# GPIO_GPIO_00600000h register map
Vendor: Texas Instruments
Peripheral module from a debugger description file (folder AM275x).
Registers are 32-bit, access not given, reset 0x0 unless marked. A register's access mark holds for its fields unless they carry their own. Offsets are as the file gives them; lines under a group give offsets from that group; [hi:lo] are bit positions; {n}, {i} and the like mark numbered series; 'fields as' and 'values as' point back to an identical list; <NAME> marks a mode.

## gpio
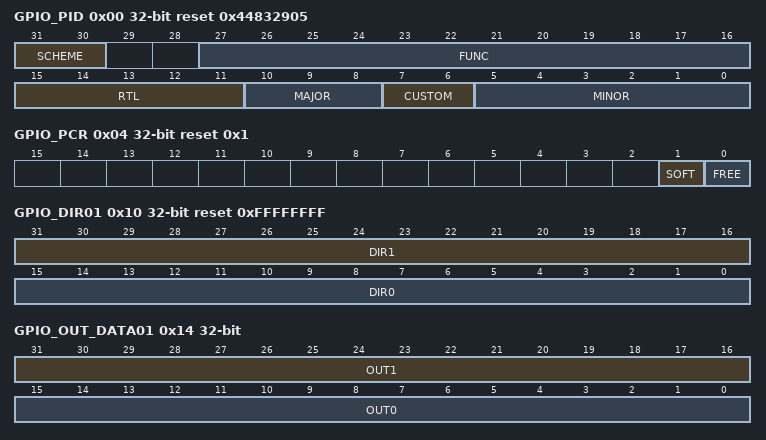
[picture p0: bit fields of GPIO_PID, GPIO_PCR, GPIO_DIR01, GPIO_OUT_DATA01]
0x00 GPIO_PID ro reset 0x44832905 — GPIO Periperal ID Register
  [31:30] SCHEME — Current scheme Reset Source: mod_g_srst_n
  [27:16] FUNC — Function code assigned to TCP3 Reset Source: mod_g_srst_n
  [15:11] RTL — RTL Version R code Reset Source: mod_g_srst_n
  [10:8] MAJOR — Major revision X code Reset Source: mod_g_srst_n
  [7:6] CUSTOM — Custom version code Reset Source: mod_g_srst_n
  [5:0] MINOR — Minor revision Y code Reset Source: mod_g_srst_n
0x04 GPIO_PCR ro reset 0x1 — Peripheral Control Register
  [1] SOFT — Used in conjunction with FREE bit to determine the emulation suspend mode. Reset Source: mod_g_srst_n
  [0] FREE — For GPIO, the FREE bit is fixed at 1, which means GPIO runs free in emulation suspend. Reset Source: mod_g_srst_n
0x08 GPIO_BINTEN rw — Bit Interrupt Enable Register
  [15:0] EN — Per bank interrupt enable. 0 = disable, 1 = enable. Reset Source: mod_g_srst_n
0x10 GPIO_DIR01 rw reset 0xFFFFFFFF — Direction Register
  [31:16] DIR1 — Direction of GPIO bank 1 bits, 0 = output, 1 = input. Reset Source: mod_g_srst_n
  [15:0] DIR0 — Direction of GPIO bank 0 bits, 0 = output, 1 = input. Reset Source: mod_g_srst_n
0x14 GPIO_OUT_DATA01 rw — Output Drive State Register
  [31:16] OUT1 — Output drive state of GPIO bank 1 bits, does not affect operation when it is configured as input. Reading it returns the output drive state. Reset Source: mod_g_srst_n
  [15:0] OUT0 — Output drive state of GPIO bank 0 bits, does not affect operation when it is configured as input. Reading it returns the output drive state. Reset Source: mod_g_srst_n
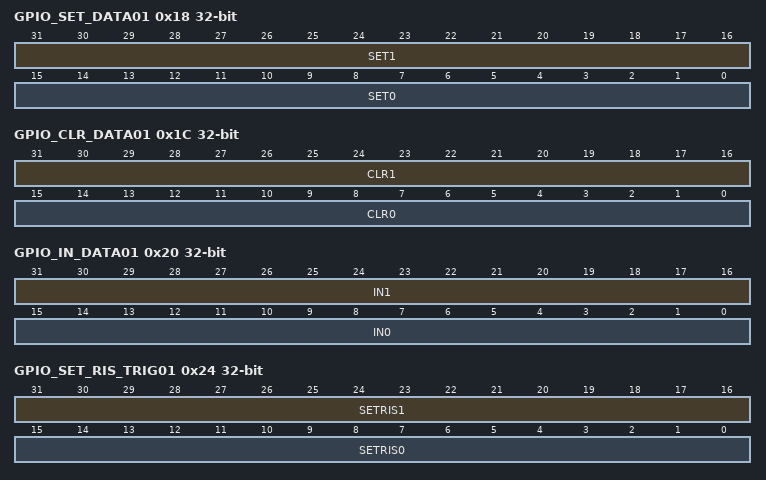
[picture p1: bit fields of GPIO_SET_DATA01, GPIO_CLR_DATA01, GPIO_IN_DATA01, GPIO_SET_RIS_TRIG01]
0x18 GPIO_SET_DATA01 — Set Output Drive State Register
  [31:16] SET1 — Writing 1 sets the output drive state of GPIO bank 1 bits. Reading it returns the output drive state. Reset Source: mod_g_srst_n (access R/W1TS)
  [15:0] SET0 — Writing 1 sets the output drive state of GPIO bank 0 bits. Reading it returns the output drive state. Reset Source: mod_g_srst_n (access R/W1TS)
0x1C GPIO_CLR_DATA01 — Clear Output Drive State Register
  [31:16] CLR1 — Writing 1 clears the output drive state of GPIO. Reading it returns the output drive state. Reset Source: mod_g_srst_n (access R/W1TC)
  [15:0] CLR0 — Writing 1 clears the output drive state of GPIO. Reading it returns the output drive state. Reset Source: mod_g_srst_n (access R/W1TC)
0x20 GPIO_IN_DATA01 ro — Bank Status Register
  [31:16] IN1 — Status of GPIO bank 1 bits. Reset Source: mod_g_srst_n
  [15:0] IN0 — Status of GPIO bank 0 bits. Reset Source: mod_g_srst_n
0x24 GPIO_SET_RIS_TRIG01 — Set Rising Edge Detection Register
  [31:16] SETRIS1 — Writing 1 enables rising edge detection for GPIO bank 1 bits. Reset Source: mod_g_srst_n (access R/W1TS)
  [15:0] SETRIS0 — Writing 1 enables rising edge detection for GPIO bank 0 bits. Reset Source: mod_g_srst_n (access R/W1TS)
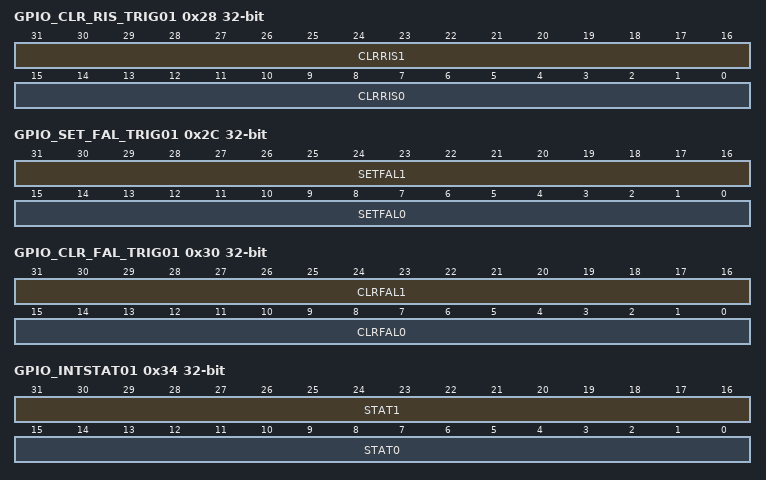
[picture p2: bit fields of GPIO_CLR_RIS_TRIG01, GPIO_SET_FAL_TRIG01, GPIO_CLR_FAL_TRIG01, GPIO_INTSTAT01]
0x28 GPIO_CLR_RIS_TRIG01 — Clear Rising Edge Detection Register
  [31:16] CLRRIS1 — Writing 1 clears rising edge detection for GPIO bank 1 bits. Reset Source: mod_g_srst_n (access R/W1TC)
  [15:0] CLRRIS0 — Writing 1 clears rising edge detection for GPIO bank 0 bits. Reset Source: mod_g_srst_n (access R/W1TC)
0x2C GPIO_SET_FAL_TRIG01 — Set Falling Edge Detection Register
  [31:16] SETFAL1 — Writing 1 enables falling edge detection for for GPIO bank 1 bits. Reset Source: mod_g_srst_n (access R/W1TS)
  [15:0] SETFAL0 — Writing 1 enables falling edge detection for for GPIO bank 0 bits. Reset Source: mod_g_srst_n (access R/W1TS)
0x30 GPIO_CLR_FAL_TRIG01 — Clear Falling Edge Detection Register
  [31:16] CLRFAL1 — Writing 1 clears falling edge detection for for GPIO bank 1 bits. Reset Source: mod_g_srst_n (access R/W1TC)
  [15:0] CLRFAL0 — Writing 1 clears falling edge detection for for GPIO bank 0 bits. Reset Source: mod_g_srst_n (access R/W1TC)
0x34 GPIO_INTSTAT01 — Bank Interrupt Status Register
  [31:16] STAT1 — Status of GPIO bank 0 bits interrupt. Reading back 1 = interrupt occurred. 0 = interrupt hasnt occurred since last cleared. Writing 1 clears the corresponding interrupt status. Reset Source: mod_g_srst_n (access R/W1TC)
  [15:0] STAT0 — Status of GPIO bank 0 bits interrupt. Reading back 1 = interrupt occurred. 0 = interrupt hasnt occurred since last cleared. Writing 1 clears the corresponding interrupt status. Reset Source: mod_g_srst_n (access R/W1TC)
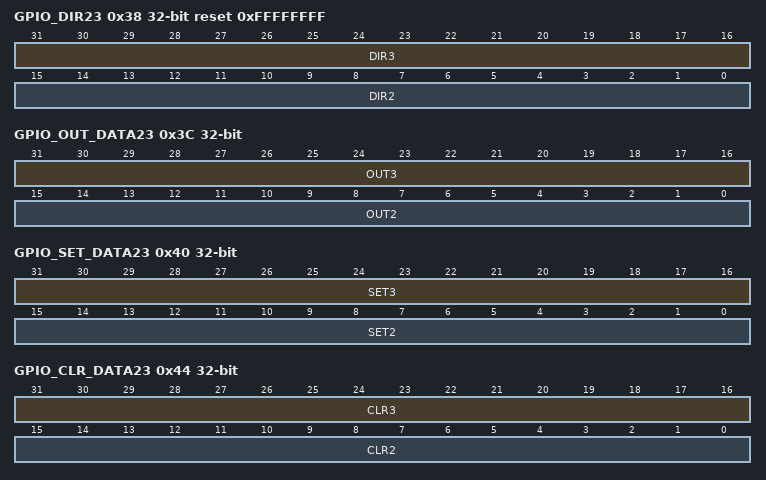
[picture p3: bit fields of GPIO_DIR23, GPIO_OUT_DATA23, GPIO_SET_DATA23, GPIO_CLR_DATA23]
0x38 GPIO_DIR23 rw reset 0xFFFFFFFF — Direction Register
  [31:16] DIR3 — Direction of GPIO bank 3 bits, 0 = output, 1 = input. Reset Source: mod_g_srst_n
  [15:0] DIR2 — Direction of GPIO bank 2 bits, 0 = output, 1 = input. Reset Source: mod_g_srst_n
0x3C GPIO_OUT_DATA23 rw — Output Drive State Register
  [31:16] OUT3 — Output drive state of GPIO bank 3 bits, does not affect operation when it is configured as input. Reading it returns the output drive state. Reset Source: mod_g_srst_n
  [15:0] OUT2 — Output drive state of GPIO bank 2 bits, does not affect operation when it is configured as input. Reading it returns the output drive state. Reset Source: mod_g_srst_n
0x40 GPIO_SET_DATA23 — Set Output Drive State Register
  [31:16] SET3 — Writing 1 sets the output drive state of GPIO bank 3 bits. Reading it returns the output drive state. Reset Source: mod_g_srst_n (access R/W1TS)
  [15:0] SET2 — Writing 1 sets the output drive state of GPIO bank 2 bits. Reading it returns the output drive state. Reset Source: mod_g_srst_n (access R/W1TS)
0x44 GPIO_CLR_DATA23 — Clear Output Drive State Register
  [31:16] CLR3 — Writing 1 clears the output drive state of GPIO. Reading it returns the output drive state. Reset Source: mod_g_srst_n (access R/W1TC)
  [15:0] CLR2 — Writing 1 clears the output drive state of GPIO. Reading it returns the output drive state. Reset Source: mod_g_srst_n (access R/W1TC)
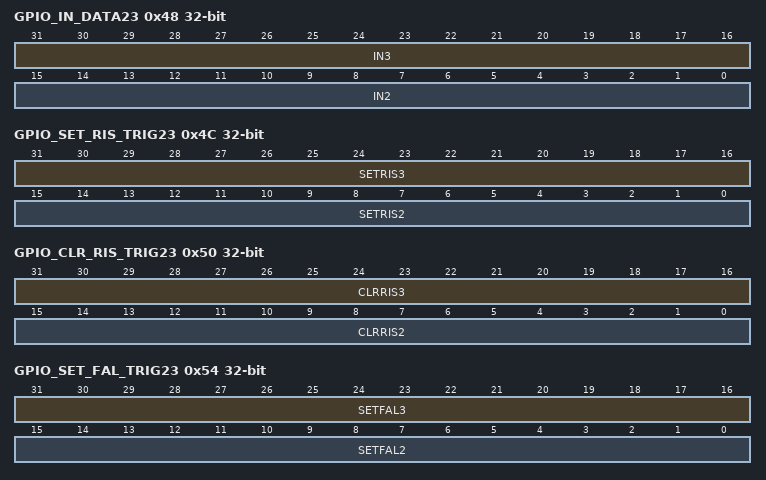
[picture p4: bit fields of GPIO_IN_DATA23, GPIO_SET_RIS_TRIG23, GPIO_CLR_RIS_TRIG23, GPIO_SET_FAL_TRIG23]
0x48 GPIO_IN_DATA23 ro — Bank Status Register
  [31:16] IN3 — Status of GPIO bank 3 bits. Reset Source: mod_g_srst_n
  [15:0] IN2 — Status of GPIO bank 2 bits. Reset Source: mod_g_srst_n
0x4C GPIO_SET_RIS_TRIG23 — Set Rising Edge Detection Register
  [31:16] SETRIS3 — Writing 1 enables rising edge detection for GPIO bank 3 bits. Reset Source: mod_g_srst_n (access R/W1TS)
  [15:0] SETRIS2 — Writing 1 enables rising edge detection for GPIO bank 2 bits. Reset Source: mod_g_srst_n (access R/W1TS)
0x50 GPIO_CLR_RIS_TRIG23 — Clear Rising Edge Detection Register
  [31:16] CLRRIS3 — Writing 1 clears rising edge detection for GPIO bank 3 bits. Reset Source: mod_g_srst_n (access R/W1TC)
  [15:0] CLRRIS2 — Writing 1 clears rising edge detection for GPIO bank 2 bits. Reset Source: mod_g_srst_n (access R/W1TC)
0x54 GPIO_SET_FAL_TRIG23 — Set Falling Edge Detection Register
  [31:16] SETFAL3 — Writing 1 enables falling edge detection for for GPIO bank 3 bits. Reset Source: mod_g_srst_n (access R/W1TS)
  [15:0] SETFAL2 — Writing 1 enables falling edge detection for for GPIO bank 2 bits. Reset Source: mod_g_srst_n (access R/W1TS)
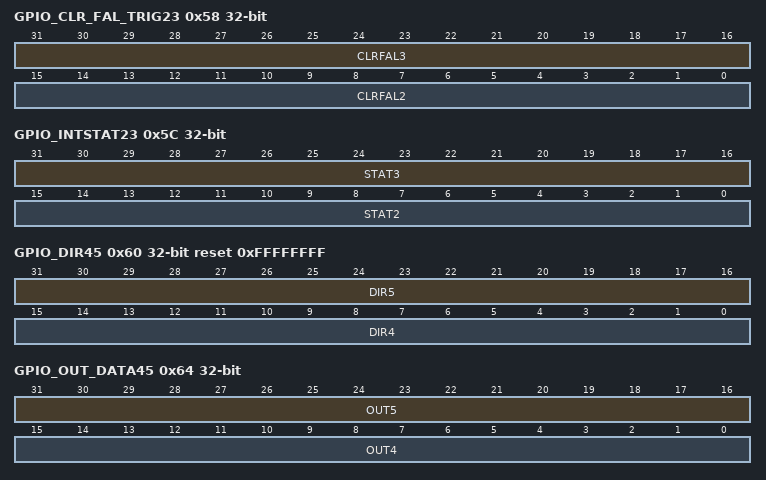
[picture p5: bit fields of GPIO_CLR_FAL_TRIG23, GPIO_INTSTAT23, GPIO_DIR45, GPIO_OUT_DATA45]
0x58 GPIO_CLR_FAL_TRIG23 — Clear Falling Edge Detection Register
  [31:16] CLRFAL3 — Writing 1 clears falling edge detection for for GPIO bank 3 bits. Reset Source: mod_g_srst_n (access R/W1TC)
  [15:0] CLRFAL2 — Writing 1 clears falling edge detection for for GPIO bank 2 bits. Reset Source: mod_g_srst_n (access R/W1TC)
0x5C GPIO_INTSTAT23 — Bank Interrupt Status Register
  [31:16] STAT3 — Status of GPIO bank 2 bits interrupt. Reading back 1 = interrupt occurred. 0 = interrupt hasnt occurred since last cleared. Writing 1 clears the corresponding interrupt status. Reset Source: mod_g_srst_n (access R/W1TC)
  [15:0] STAT2 — Status of GPIO bank 2 bits interrupt. Reading back 1 = interrupt occurred. 0 = interrupt hasnt occurred since last cleared. Writing 1 clears the corresponding interrupt status. Reset Source: mod_g_srst_n (access R/W1TC)
0x60 GPIO_DIR45 rw reset 0xFFFFFFFF — Direction Register
  [31:16] DIR5 — Direction of GPIO bank 5 bits, 0 = output, 1 = input. Reset Source: mod_g_srst_n
  [15:0] DIR4 — Direction of GPIO bank 4 bits, 0 = output, 1 = input. Reset Source: mod_g_srst_n
0x64 GPIO_OUT_DATA45 rw — Output Drive State Register
  [31:16] OUT5 — Output drive state of GPIO bank 5 bits, does not affect operation when it is configured as input. Reading it returns the output drive state. Reset Source: mod_g_srst_n
  [15:0] OUT4 — Output drive state of GPIO bank 4 bits, does not affect operation when it is configured as input. Reading it returns the output drive state. Reset Source: mod_g_srst_n
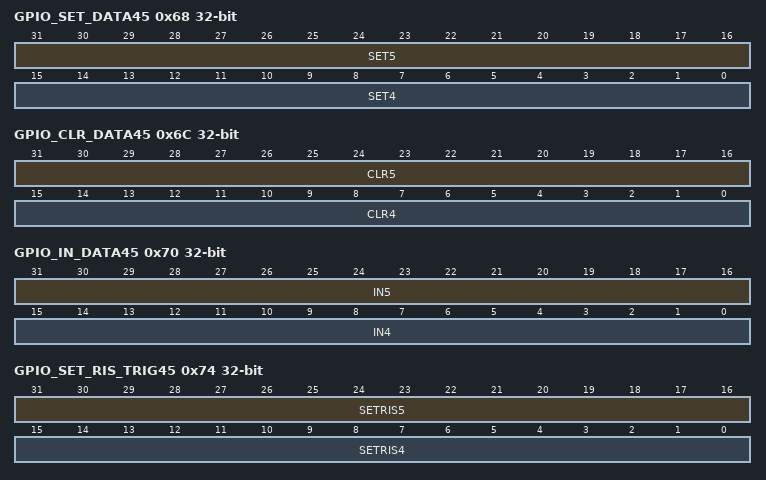
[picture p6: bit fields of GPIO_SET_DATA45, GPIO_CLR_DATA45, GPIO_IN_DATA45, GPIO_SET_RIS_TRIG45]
0x68 GPIO_SET_DATA45 — Set Output Drive State Register
  [31:16] SET5 — Writing 1 sets the output drive state of GPIO bank 5 bits. Reading it returns the output drive state. Reset Source: mod_g_srst_n (access R/W1TS)
  [15:0] SET4 — Writing 1 sets the output drive state of GPIO bank 4 bits. Reading it returns the output drive state. Reset Source: mod_g_srst_n (access R/W1TS)
0x6C GPIO_CLR_DATA45 — Clear Output Drive State Register
  [31:16] CLR5 — Writing 1 clears the output drive state of GPIO. Reading it returns the output drive state. Reset Source: mod_g_srst_n (access R/W1TC)
  [15:0] CLR4 — Writing 1 clears the output drive state of GPIO. Reading it returns the output drive state. Reset Source: mod_g_srst_n (access R/W1TC)
0x70 GPIO_IN_DATA45 ro — Bank Status Register
  [31:16] IN5 — Status of GPIO bank 5 bits. Reset Source: mod_g_srst_n
  [15:0] IN4 — Status of GPIO bank 4 bits. Reset Source: mod_g_srst_n
0x74 GPIO_SET_RIS_TRIG45 — Set Rising Edge Detection Register
  [31:16] SETRIS5 — Writing 1 enables rising edge detection for GPIO bank 5 bits. Reset Source: mod_g_srst_n (access R/W1TS)
  [15:0] SETRIS4 — Writing 1 enables rising edge detection for GPIO bank 4 bits. Reset Source: mod_g_srst_n (access R/W1TS)
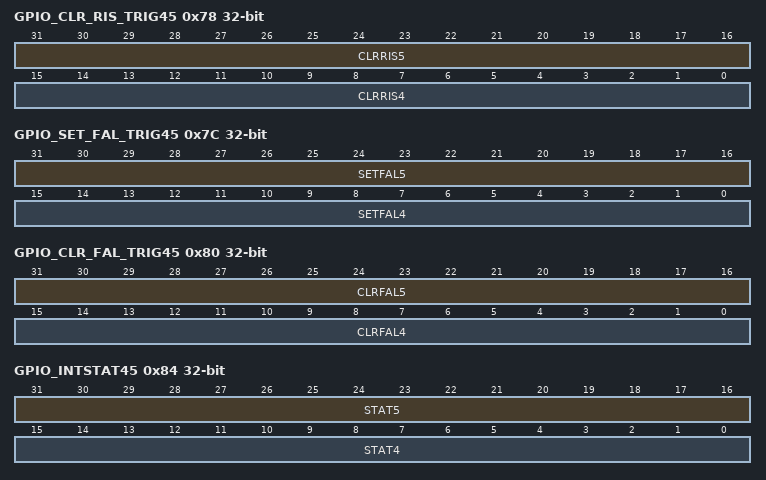
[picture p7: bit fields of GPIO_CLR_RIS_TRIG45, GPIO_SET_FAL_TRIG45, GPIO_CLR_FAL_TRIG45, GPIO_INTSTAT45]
0x78 GPIO_CLR_RIS_TRIG45 — Clear Rising Edge Detection Register
  [31:16] CLRRIS5 — Writing 1 clears rising edge detection for GPIO bank 5 bits. Reset Source: mod_g_srst_n (access R/W1TC)
  [15:0] CLRRIS4 — Writing 1 clears rising edge detection for GPIO bank 4 bits. Reset Source: mod_g_srst_n (access R/W1TC)
0x7C GPIO_SET_FAL_TRIG45 — Set Falling Edge Detection Register
  [31:16] SETFAL5 — Writing 1 enables falling edge detection for for GPIO bank 5 bits. Reset Source: mod_g_srst_n (access R/W1TS)
  [15:0] SETFAL4 — Writing 1 enables falling edge detection for for GPIO bank 4 bits. Reset Source: mod_g_srst_n (access R/W1TS)
0x80 GPIO_CLR_FAL_TRIG45 — Clear Falling Edge Detection Register
  [31:16] CLRFAL5 — Writing 1 clears falling edge detection for for GPIO bank 5 bits. Reset Source: mod_g_srst_n (access R/W1TC)
  [15:0] CLRFAL4 — Writing 1 clears falling edge detection for for GPIO bank 4 bits. Reset Source: mod_g_srst_n (access R/W1TC)
0x84 GPIO_INTSTAT45 — Bank Interrupt Status Register
  [31:16] STAT5 — Status of GPIO bank 4 bits interrupt. Reading back 1 = interrupt occurred. 0 = interrupt hasnt occurred since last cleared. Writing 1 clears the corresponding interrupt status. Reset Source: mod_g_srst_n (access R/W1TC)
  [15:0] STAT4 — Status of GPIO bank 4 bits interrupt. Reading back 1 = interrupt occurred. 0 = interrupt hasnt occurred since last cleared. Writing 1 clears the corresponding interrupt status. Reset Source: mod_g_srst_n (access R/W1TC)
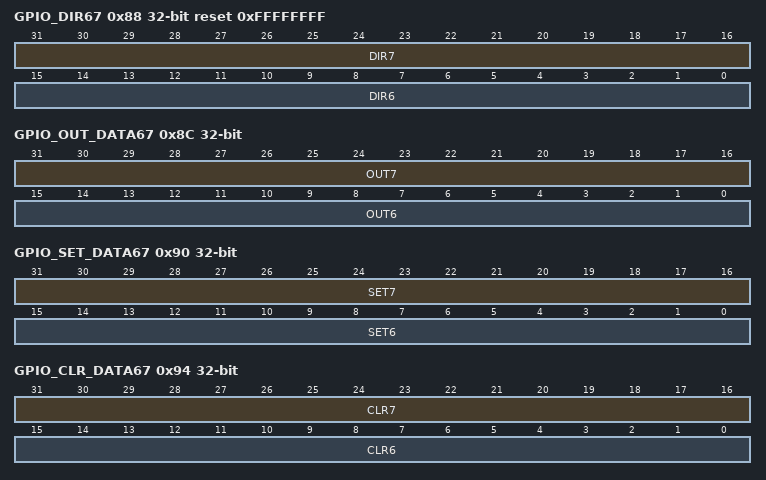
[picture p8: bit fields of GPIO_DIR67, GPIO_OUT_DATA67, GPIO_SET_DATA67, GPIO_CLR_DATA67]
0x88 GPIO_DIR67 rw reset 0xFFFFFFFF — Direction Register
  [31:16] DIR7 — Direction of GPIO bank 7 bits, 0 = output, 1 = input. Reset Source: mod_g_srst_n
  [15:0] DIR6 — Direction of GPIO bank 6 bits, 0 = output, 1 = input. Reset Source: mod_g_srst_n
0x8C GPIO_OUT_DATA67 rw — Output Drive State Register
  [31:16] OUT7 — Output drive state of GPIO bank 7 bits, does not affect operation when it is configured as input. Reading it returns the output drive state. Reset Source: mod_g_srst_n
  [15:0] OUT6 — Output drive state of GPIO bank 6 bits, does not affect operation when it is configured as input. Reading it returns the output drive state. Reset Source: mod_g_srst_n
0x90 GPIO_SET_DATA67 — Set Output Drive State Register
  [31:16] SET7 — Writing 1 sets the output drive state of GPIO bank 7 bits. Reading it returns the output drive state. Reset Source: mod_g_srst_n (access R/W1TS)
  [15:0] SET6 — Writing 1 sets the output drive state of GPIO bank 6 bits. Reading it returns the output drive state. Reset Source: mod_g_srst_n (access R/W1TS)
0x94 GPIO_CLR_DATA67 — Clear Output Drive State Register
  [31:16] CLR7 — Writing 1 clears the output drive state of GPIO. Reading it returns the output drive state. Reset Source: mod_g_srst_n (access R/W1TC)
  [15:0] CLR6 — Writing 1 clears the output drive state of GPIO. Reading it returns the output drive state. Reset Source: mod_g_srst_n (access R/W1TC)
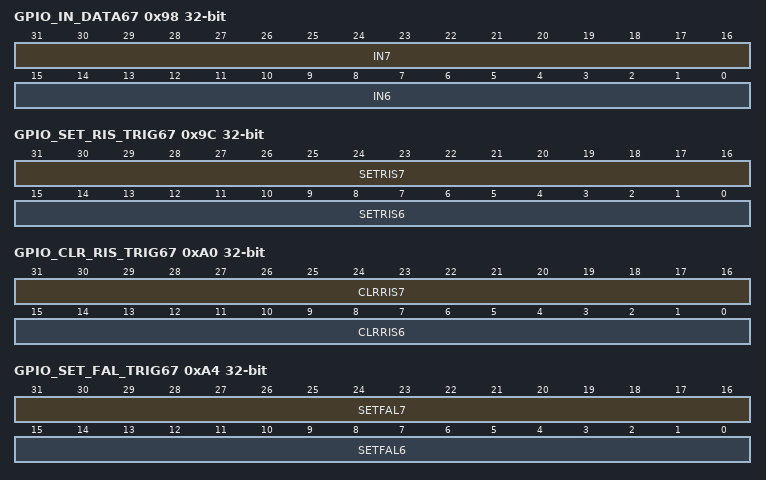
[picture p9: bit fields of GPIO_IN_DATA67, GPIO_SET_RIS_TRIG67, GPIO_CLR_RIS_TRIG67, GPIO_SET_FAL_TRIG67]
0x98 GPIO_IN_DATA67 ro — Bank Status Register
  [31:16] IN7 — Status of GPIO bank 7 bits. Reset Source: mod_g_srst_n
  [15:0] IN6 — Status of GPIO bank 6 bits. Reset Source: mod_g_srst_n
0x9C GPIO_SET_RIS_TRIG67 — Set Rising Edge Detection Register
  [31:16] SETRIS7 — Writing 1 enables rising edge detection for GPIO bank 7 bits. Reset Source: mod_g_srst_n (access R/W1TS)
  [15:0] SETRIS6 — Writing 1 enables rising edge detection for GPIO bank 6 bits. Reset Source: mod_g_srst_n (access R/W1TS)
0xA0 GPIO_CLR_RIS_TRIG67 — Clear Rising Edge Detection Register
  [31:16] CLRRIS7 — Writing 1 clears rising edge detection for GPIO bank 7 bits. Reset Source: mod_g_srst_n (access R/W1TC)
  [15:0] CLRRIS6 — Writing 1 clears rising edge detection for GPIO bank 6 bits. Reset Source: mod_g_srst_n (access R/W1TC)
0xA4 GPIO_SET_FAL_TRIG67 — Set Falling Edge Detection Register
  [31:16] SETFAL7 — Writing 1 enables falling edge detection for for GPIO bank 7 bits. Reset Source: mod_g_srst_n (access R/W1TS)
  [15:0] SETFAL6 — Writing 1 enables falling edge detection for for GPIO bank 6 bits. Reset Source: mod_g_srst_n (access R/W1TS)
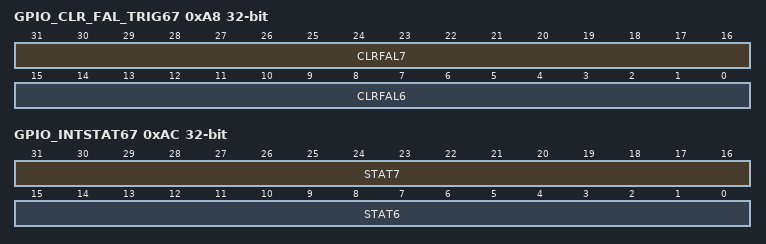
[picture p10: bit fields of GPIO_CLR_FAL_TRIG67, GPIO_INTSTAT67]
0xA8 GPIO_CLR_FAL_TRIG67 — Clear Falling Edge Detection Register
  [31:16] CLRFAL7 — Writing 1 clears falling edge detection for for GPIO bank 7 bits. Reset Source: mod_g_srst_n (access R/W1TC)
  [15:0] CLRFAL6 — Writing 1 clears falling edge detection for for GPIO bank 6 bits. Reset Source: mod_g_srst_n (access R/W1TC)
0xAC GPIO_INTSTAT67 — Bank Interrupt Status Register
  [31:16] STAT7 — Status of GPIO bank 6 bits interrupt. Reading back 1 = interrupt occurred. 0 = interrupt hasnt occurred since last cleared. Writing 1 clears the corresponding interrupt status. Reset Source: mod_g_srst_n (access R/W1TC)
  [15:0] STAT6 — Status of GPIO bank 6 bits interrupt. Reading back 1 = interrupt occurred. 0 = interrupt hasnt occurred since last cleared. Writing 1 clears the corresponding interrupt status. Reset Source: mod_g_srst_n (access R/W1TC)
0xB0 GPIO_DIR8 rw reset 0xFFFF — Direction Register
  [15:0] DIR8 — Direction of GPIO bank 8 bits, 0 = output, 1 = input. Reset Source: mod_g_srst_n
0xB4 GPIO_OUT_DATA8 rw — Output Drive State Register
  [15:0] OUT8 — Output drive state of GPIO bank 8 bits, does not affect operation when it is configured as input. Reading it returns the output drive state. Reset Source: mod_g_srst_n
0xB8 GPIO_SET_DATA8 — Set Output Drive State Register
  [15:0] SET8 — Writing 1 sets the output drive state of GPIO bank 8 bits. Reading it returns the output drive state. Reset Source: mod_g_srst_n (access R/W1TS)
0xBC GPIO_CLR_DATA8 — Clear Output Drive State Register
  [15:0] CLR8 — Writing 1 clears the output drive state of GPIO. Reading it returns the output drive state. Reset Source: mod_g_srst_n (access R/W1TC)
0xC0 GPIO_IN_DATA8 ro — Bank Status Register
  [15:0] IN8 — Status of GPIO bank 8 bits. Reset Source: mod_g_srst_n
0xC4 GPIO_SET_RIS_TRIG8 — Set Rising Edge Detection Register
  [15:0] SETRIS8 — Writing 1 enables rising edge detection for GPIO bank 8 bits. Reset Source: mod_g_srst_n (access R/W1TS)
0xC8 GPIO_CLR_RIS_TRIG8 — Clear Rising Edge Detection Register
  [15:0] CLRRIS8 — Writing 1 clears rising edge detection for GPIO bank 8 bits. Reset Source: mod_g_srst_n (access R/W1TC)
0xCC GPIO_SET_FAL_TRIG8 — Set Falling Edge Detection Register
  [15:0] SETFAL8 — Writing 1 enables falling edge detection for for GPIO bank 8 bits. Reset Source: mod_g_srst_n (access R/W1TS)
0xD0 GPIO_CLR_FAL_TRIG8 — Clear Falling Edge Detection Register
  [15:0] CLRFAL8 — Writing 1 clears falling edge detection for for GPIO bank 8 bits. Reset Source: mod_g_srst_n (access R/W1TC)
0xD4 GPIO_INTSTAT8 — Bank Interrupt Status Register
  [15:0] STAT8 — Status of GPIO bank 8 bits interrupt. Reading back 1 = interrupt occurred. 0 = interrupt hasnt occurred since last cleared. Writing 1 clears the corresponding interrupt status. Reset Source: mod_g_srst_n (access R/W1TC)
